AUTOSAR XML (schema 4-0-3)
standard types defined: Boolean, UInt32, UInt8
package /AUTOSAR_Platform/DataConstrs
  range DC_Boolean: raw 0..1
  range DC_UInt8: raw 0..255
package /PATAC/MSM/ComponentTypes
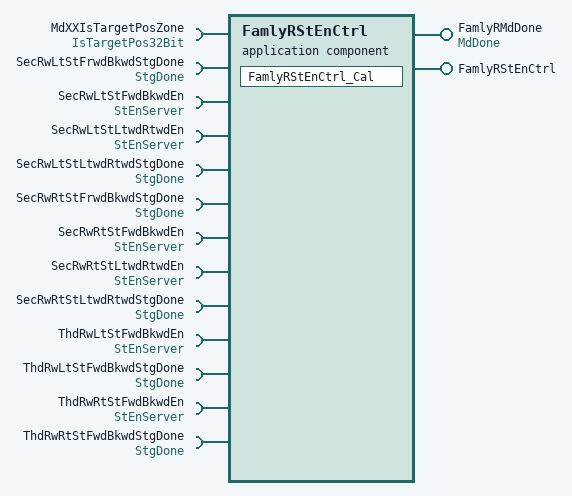
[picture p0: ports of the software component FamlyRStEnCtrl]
  application sw component type FamlyRStEnCtrl
    provide port FamlyRMdDone: nonqueued-sender-com-spec{data-element=MdDone/Val, init-value=0}, provided-interface=MdDone
    provide port FamlyRStEnCtrl: server-com-spec{operation=Cal, queue-length=1}, provided-interface=FamlyRStEnCtrl
    13 x require port:
      MdXXIsTargetPosZone: nonqueued-receiver-com-spec{data-element=IsTargetPos32Bit/Val, filter=data-filter-type=ALWAYS, init-value=0}, required-interface=IsTargetPos32Bit
      SecRwLtStFrwdBkwdStgDone: nonqueued-receiver-com-spec{data-element=StgDone/Val, filter=data-filter-type=ALWAYS, init-value=0}, required-interface=StgDone
      SecRwLtStFwdBkwdEn: required-com-specs=[Clear, Get, Set], required-interface=StEnServer
      SecRwLtStLtwdRtwdEn: required-com-specs=[Clear, Get, Set], required-interface=StEnServer
      SecRwLtStLtwdRtwdStgDone: nonqueued-receiver-com-spec{data-element=StgDone/Val, filter=data-filter-type=ALWAYS, init-value=0}, required-interface=StgDone
      SecRwRtStFrwdBkwdStgDone: nonqueued-receiver-com-spec{data-element=StgDone/Val, filter=data-filter-type=ALWAYS, init-value=0}, required-interface=StgDone
      SecRwRtStFwdBkwdEn: required-com-specs=[Clear, Get, Set], required-interface=StEnServer
      SecRwRtStLtwdRtwdEn: required-com-specs=[Clear, Get, Set], required-interface=StEnServer
      SecRwRtStLtwdRtwdStgDone: nonqueued-receiver-com-spec{data-element=StgDone/Val, filter=data-filter-type=ALWAYS, init-value=0}, required-interface=StgDone
      ThdRwLtStFwdBkwdEn: required-com-specs=[Clear, Get, Set], required-interface=StEnServer
      ThdRwLtStFwdBkwdStgDone: nonqueued-receiver-com-spec{data-element=StgDone/Val, filter=data-filter-type=ALWAYS, init-value=0}, required-interface=StgDone
      ThdRwRtStFwdBkwdEn: required-com-specs=[Clear, Get, Set], required-interface=StEnServer
      ThdRwRtStFwdBkwdStgDone: nonqueued-receiver-com-spec{data-element=StgDone/Val, filter=data-filter-type=ALWAYS, init-value=0}, required-interface=StgDone
    behavior FamlyRStEnCtrl_InternalBehavior
      operation invoked event OIT_FamlyRStEnCtrl_Cal_FamlyRStEnCtrl_Cal: start-on-event=FamlyRStEnCtrl_Cal, operation=FamlyRStEnCtrl.Cal
      runnable FamlyRStEnCtrl_Cal
        data-receive-point-by-arguments:
          7 x access:
            REC_MdXXIsTargetPosZone_Val: accessed-variable=MdXXIsTargetPosZone.Val
            REC_SecRwLtStFrwdBkwdStgDone_Val: accessed-variable=SecRwLtStFrwdBkwdStgDone.Val
            REC_SecRwLtStLtwdRtwdStgDone_Val: accessed-variable=SecRwLtStLtwdRtwdStgDone.Val
            REC_SecRwRtStFrwdBkwdStgDone_Val: accessed-variable=SecRwRtStFrwdBkwdStgDone.Val
            REC_SecRwRtStLtwdRtwdStgDone_Val: accessed-variable=SecRwRtStLtwdRtwdStgDone.Val
            REC_ThdRwLtStFwdBkwdStgDone_Val: accessed-variable=ThdRwLtStFwdBkwdStgDone.Val
            REC_ThdRwRtStFwdBkwdStgDone_Val: accessed-variable=ThdRwRtStFwdBkwdStgDone.Val
        data-send-points:
          access SEND_FamlyRMdDone_Val: accessed-variable=FamlyRMdDone.Val
        12 x sync call, all with timeout=0:
          SC_SecRwLtStFwdBkwdEn_Clear: operation=SecRwLtStFwdBkwdEn.Clear
          SC_SecRwLtStFwdBkwdEn_Set: operation=SecRwLtStFwdBkwdEn.Set
          SC_SecRwLtStLtwdRtwdEn_Clear: operation=SecRwLtStLtwdRtwdEn.Clear
          SC_SecRwLtStLtwdRtwdEn_Set: operation=SecRwLtStLtwdRtwdEn.Set
          SC_SecRwRtStFwdBkwdEn_Clear: operation=SecRwRtStFwdBkwdEn.Clear
          SC_SecRwRtStFwdBkwdEn_Set: operation=SecRwRtStFwdBkwdEn.Set
          SC_SecRwRtStLtwdRtwdEn_Clear: operation=SecRwRtStLtwdRtwdEn.Clear
          SC_SecRwRtStLtwdRtwdEn_Set: operation=SecRwRtStLtwdRtwdEn.Set
          SC_ThdRwLtStFwdBkwdEn_Clear: operation=ThdRwLtStFwdBkwdEn.Clear
          SC_ThdRwLtStFwdBkwdEn_Set: operation=ThdRwLtStFwdBkwdEn.Set
          SC_ThdRwRtStFwdBkwdEn_Clear: operation=ThdRwRtStFwdBkwdEn.Clear
          SC_ThdRwRtStFwdBkwdEn_Set: operation=ThdRwRtStFwdBkwdEn.Set
  swc implementation FamlyRStEnCtrl_Implementation: behavior=FamlyRStEnCtrl_InternalBehavior
    code-descriptors:
      code Default: artifact-descriptors=autosar-engineering-object={short-label=Default, category=SWSRC}
package /PATAC/MSM/ModeAdjust/PortInterface
  client server interface FamlyRStEnCtrl
    operation Cal
  client server interface StEnServer
    operation Clear
      arg data: type=UInt8, direction=IN, server-argument-impl-policy=USE-ARGUMENT-TYPE
    operation Get
      arg data: type=UInt32, direction=OUT, server-argument-impl-policy=USE-ARGUMENT-TYPE
    operation Set
      arg data: type=UInt8, direction=IN, server-argument-impl-policy=USE-ARGUMENT-TYPE
  sender receiver interface IsTargetPos32Bit: invalidation-policy{data-element=IsTargetPos32Bit/Val, handle-invalid=DONT-INVALIDATE}
    data Val: type=UInt32
  sender receiver interface MdDone: invalidation-policy{data-element=MdDone/Val, handle-invalid=DONT-INVALIDATE}
    data Val: type=UInt8
  sender receiver interface StgDone: invalidation-policy{data-element=StgDone/Val, handle-invalid=DONT-INVALIDATE}
    data Val: type=Boolean
